# EFR32FG25A221F1920IM56 register map
Vendor: Silicon Labs; Series: EFR32; File version: B
Registers are 32-bit, read-write, reset 0x0 unless marked. A register's access mark holds for its fields unless they carry their own. Offsets are from the block's base; [hi:lo] are bit positions; {n}, {i} and the like mark numbered series.

## SMU_NS — SMU_NS Registers
Base 0x54008000
Same registers: SMU_S 0x44008000
0x00 IPVERSION ro reset 0x4
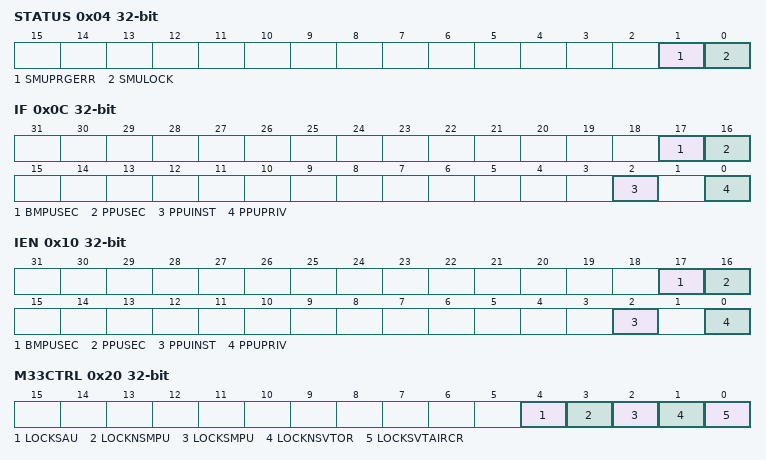
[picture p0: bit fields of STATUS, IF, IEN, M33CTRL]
0x04 STATUS ro
  [1] SMUPRGERR — SMU Programming Error
  [0] SMULOCK
    0=UNLOCKED; 1=LOCKED
0x08 LOCK wo
  [23:0] SMULOCKKEY
    0xACCE55=UNLOCK (Unlocks Registers)
0x0C IF
  [17] BMPUSEC — BMPU Security Interrupt Flag
  [16] PPUSEC — PPU Security Interrupt Flag
  [2] PPUINST — PPU Instruction Interrupt Flag
  [0] PPUPRIV — PPU Privilege Interrupt Flag
0x10 IEN
  [17] BMPUSEC — BMPU Security Interrupt Enable
  [16] PPUSEC — PPU Security Interrupt Enable
  [2] PPUINST — PPU Instruction Interrupt Enable
  [0] PPUPRIV — PPU Privilege Interrupt Enable
0x20 M33CTRL — Holds the M33 control settings
  [4] LOCKSAU — New BitField
  [3] LOCKNSMPU — New BitField
  [2] LOCKSMPU — New BitField
  [1] LOCKNSVTOR — New BitField
  [0] LOCKSVTAIRCR — New BitField
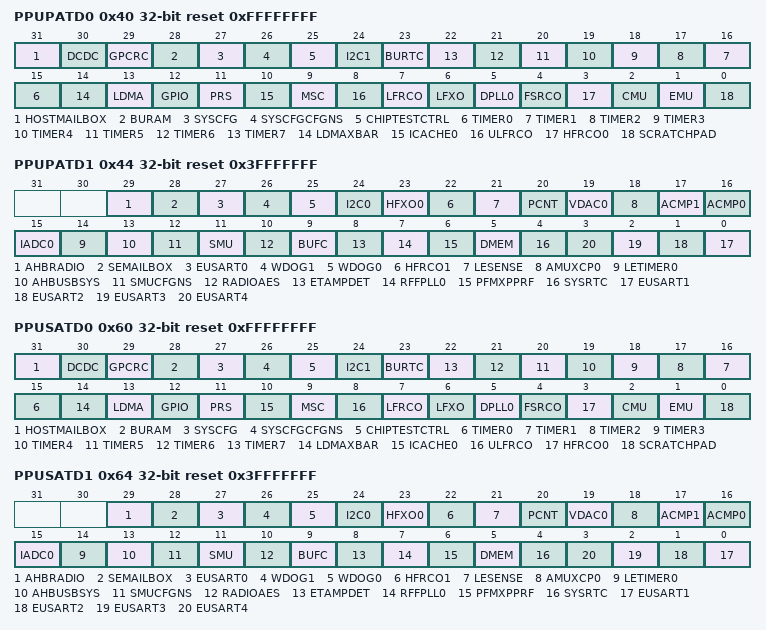
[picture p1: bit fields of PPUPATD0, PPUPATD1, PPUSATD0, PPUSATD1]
0x40 PPUPATD0 reset 0xFFFFFFFF — Set peripheral bits to 1 to mark as privileged access only
  [31] HOSTMAILBOX — HOSTMAILBOX Privileged Access
  [30] DCDC — DCDC Privileged Access
  [29] GPCRC — GPCRC Privileged Access
  [28] BURAM — BURAM Privileged Access
  [27] SYSCFG — SYSCFG Privileged Access
  [26] SYSCFGCFGNS — SYSCFGCFGNS Privileged Access
  [25] CHIPTESTCTRL — CHIPTESTCTRL Privileged Access
  [24] I2C1 — I2C1 Privileged Access
  [23] BURTC — BURTC Privileged Access
  [n+15] TIMER{n} (n=0..7) — TIMER{n} Privileged Access
  [14] LDMAXBAR — LDMAXBAR Privileged Access
  [13] LDMA — LDMA Privileged Access
  [12] GPIO — GPIO Privileged Access
  [11] PRS — PRS Privileged Access
  [10] ICACHE0 — ICACHE0 Privileged Access
  [9] MSC — MSC Privileged Access
  [8] ULFRCO — ULFRCO Privileged Access
  [7] LFRCO — LFRCO Privileged Access
  [6] LFXO — LFXO Privileged Access
  [5] DPLL0 — DPLL0 Privileged Access
  [4] FSRCO — FSRCO Privileged Access
  [3] HFRCO0 — HFRCO0 Privileged Access
  [2] CMU — CMU Privileged Access
  [1] EMU — EMU Privileged Access
  [0] SCRATCHPAD — SCRATCHPAD Privileged Access
0x44 PPUPATD1 reset 0x3FFFFFFF — Set peripheral bits to 1 to mark as privileged access only
  [29] AHBRADIO — AHBRADIO Privileged Access
  [28] SEMAILBOX — SEMAILBOX Privileged Access
  [27] EUSART0 — EUSART0 Privileged Access
  [26] WDOG1 — WDOG1 Privileged Access
  [25] WDOG0 — WDOG0 Privileged Access
  [24] I2C0 — I2C0 Privileged Access
  [23] HFXO0 — HFXO0 Privileged Access
  [22] HFRCO1 — HFRCO1 Privileged Access
  [21] LESENSE — LESENSE Privileged Access
  [20] PCNT — PCNT Privileged Access
  [19] VDAC0 — VDAC0 Privileged Access
  [18] AMUXCP0 — AMUXCP0 Privileged Access
  [17] ACMP1 — ACMP1 Privileged Access
  [16] ACMP0 — ACMP0 Privileged Access
  [15] IADC0 — IADC0 Privileged Access
  [14] LETIMER0 — LETIMER0 Privileged Access
  [13] AHBUSBSYS — AHBUSBSYS Privileged Access
  [12] SMUCFGNS — SMUCFGNS Privileged Access
  [11] SMU — SMU Privileged Access
  [10] RADIOAES — RADIOAES Privileged Access
  [9] BUFC — BUFC Privileged Access
  [8] ETAMPDET — ETAMPDET Privileged Access
  [7] RFFPLL0 — RFFPLL0 Privileged Access
  [6] PFMXPPRF — PFMXPPRF Privileged Access
  [5] DMEM — DMEM Privileged Access
  [4] SYSRTC — SYSRTC Privileged Access
  [n-1] EUSART{n} (n=1..4) — EUSART{n} Privileged Access
0x60 PPUSATD0 reset 0xFFFFFFFF — Set peripheral bits to 1 to mark as secure access only
  [31] HOSTMAILBOX — HOSTMAILBOX Secure Access
  [30] DCDC — DCDC Secure Access
  [29] GPCRC — GPCRC Secure Access
  [28] BURAM — BURAM Secure Access
  [27] SYSCFG — SYSCFG Secure Access
  [26] SYSCFGCFGNS — SYSCFGCFGNS Secure Access
  [25] CHIPTESTCTRL — CHIPTESTCTRL Secure Access
  [24] I2C1 — I2C1 Secure Access
  [23] BURTC — BURTC Secure Access
  [n+15] TIMER{n} (n=0..7) — TIMER{n} Secure Access
  [14] LDMAXBAR — LDMAXBAR Secure Access
  [13] LDMA — LDMA Secure Access
  [12] GPIO — GPIO Secure Access
  [11] PRS — PRS Secure Access
  [10] ICACHE0 — ICACHE0 Secure Access
  [9] MSC — MSC Secure Access
  [8] ULFRCO — ULFRCO Secure Access
  [7] LFRCO — LFRCO Secure Access
  [6] LFXO — LFXO Secure Access
  [5] DPLL0 — DPLL0 Secure Access
  [4] FSRCO — FSRCO Secure Access
  [3] HFRCO0 — HFRCO0 Secure Access
  [2] CMU — CMU Secure Access
  [1] EMU — EMU Secure Access
  [0] SCRATCHPAD — SCRATCHPAD Secure Access
0x64 PPUSATD1 reset 0x3FFFFFFF — Set peripheral bits to 1 to mark as secure access only
  [29] AHBRADIO — AHBRADIO Secure Access
  [28] SEMAILBOX — SEMAILBOX Secure Access
  [27] EUSART0 — EUSART0 Secure Access
  [26] WDOG1 — WDOG1 Secure Access
  [25] WDOG0 — WDOG0 Secure Access
  [24] I2C0 — I2C0 Secure Access
  [23] HFXO0 — HFXO0 Secure Access
  [22] HFRCO1 — HFRCO1 Secure Access
  [21] LESENSE — LESENSE Secure Access
  [20] PCNT — PCNT Secure Access
  [19] VDAC0 — VDAC0 Secure Access
  [18] AMUXCP0 — AMUXCP0 Secure Access
  [17] ACMP1 — ACMP1 Secure Access
  [16] ACMP0 — ACMP0 Secure Access
  [15] IADC0 — IADC0 Secure Access
  [14] LETIMER0 — LETIMER0 Secure Access
  [13] AHBUSBSYS — AHBUSBSYS Secure Access
  [12] SMUCFGNS — SMUCFGNS Secure Access
  [11] SMU — SMU Secure Access
  [10] RADIOAES — RADIOAES Secure Access
  [9] BUFC — BUFC Secure Access
  [8] ETAMPDET — ETAMPDET Secure Access
  [7] RFFPLL0 — RFFPLL0 Secure Access
  [6] PFMXPPRF — PFMXPPRF Secure Access
  [5] DMEM — DMEM Secure Access
  [4] SYSRTC — SYSRTC Secure Access
  [n-1] EUSART{n} (n=1..4) — EUSART{n} Secure Access
0x140 PPUFS ro
  [7:0] PPUFSPERIPHID — Peripheral ID
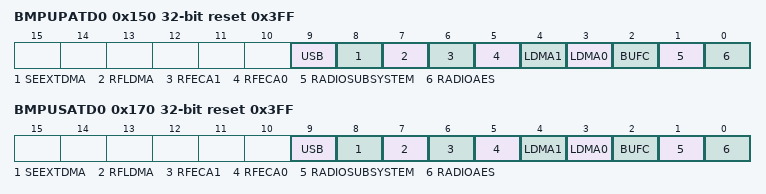
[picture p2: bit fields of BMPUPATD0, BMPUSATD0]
0x150 BMPUPATD0 reset 0x3FF — Set master bits to 1 to mark as a privileged master
  [9] USB — USB privileged mode
  [8] SEEXTDMA — SEEXTDMA privileged mode
  [7] RFLDMA — RFLDMA privileged mode
  [6] RFECA1 — RFECA1 privileged mode
  [5] RFECA0 — RFECA0 privileged mode
  [4] LDMA1 — MCU LDMA port 1 privileged mode
  [3] LDMA0 — MCU LDMA port 0 privileged mode
  [2] BUFC — BUFC privileged mode
  [1] RADIOSUBSYSTEM — RADIO subsystem manager privileged mode
  [0] RADIOAES — RADIO AES DMA privileged mode
0x170 BMPUSATD0 reset 0x3FF — Set master bits to 1 to mark as a secure master
  [9] USB — USB secure mode
  [8] SEEXTDMA — SEEXTDMA secure mode
  [7] RFLDMA — RFLDMA secure mode
  [6] RFECA1 — RFECA1 secure mode
  [5] RFECA0 — RFECA0 secure mode
  [4] LDMA1 — MCU LDMA port 1 secure mode
  [3] LDMA0 — MCU LDMA port 0 secure mode
  [2] BUFC — BUFC secure mode
  [1] RADIOSUBSYSTEM — RADIO subsystem manager secure mode
  [0] RADIOAES — RADIO AES DMA secure mode
0x250 BMPUFS ro
  [7:0] BMPUFSMASTERID — Bus Manager ID
0x254 BMPUFSADDR ro
  [31:0] BMPUFSADDR — Fault Address
0x260 ESAURTYPES0
  [12] ESAUR3NS — Region 3 Non-Secure
0x264 ESAURTYPES1
  [12] ESAUR11NS — Region 11 Non-Secure
0x270 ESAUMRB01 reset 0xA000000
  [27:12] ESAUMRB01 — Moveable Region Boundary
0x274 ESAUMRB12 reset 0xC000000
  [27:12] ESAUMRB12 — Moveable Region Boundary
0x280 ESAUMRB45 reset 0x2000000
  [27:12] ESAUMRB45 — Moveable Region Boundary
0x284 ESAUMRB56 reset 0x4000000
  [27:12] ESAUMRB56 — Moveable Region Boundary
